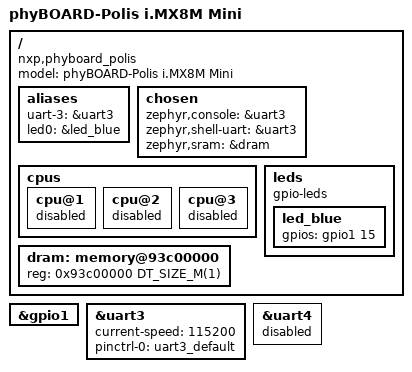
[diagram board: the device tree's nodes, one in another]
/*
 * Copyright (c) 2026 BayLibre SAS
 *
 * SPDX-License-Identifier: Apache-2.0
 */

/dts-v1/;

#include <nxp/nxp_mimx8mm_a53.dtsi>
#include <zephyr/dt-bindings/gpio/gpio.h>
#include "phyboard_polis-pinctrl.dtsi"

/ {
	model = "phyBOARD-Polis i.MX8M Mini";
	compatible = "nxp,phyboard_polis";

	aliases {
		uart-3 = &uart3;
		led0 = &led_blue;
	};

	chosen {
		zephyr,console = &uart3;
		zephyr,shell-uart = &uart3;
		/* sram node actually locates at DDR DRAM */
		zephyr,sram = &dram;
	};

	cpus {
		cpu@1 {
			status = "disabled";
		};

		cpu@2 {
			status = "disabled";
		};

		cpu@3 {
			status = "disabled";
		};
	};

	dram: memory@93c00000 {
		reg = <0x93c00000 DT_SIZE_M(1)>;
	};

	leds {
		compatible = "gpio-leds";

		led_blue: led_blue {
			gpios = <&gpio1 15 GPIO_ACTIVE_HIGH>;
		};
	};
};

&gpio1 {
	status = "okay";
};

/* UART usually used from A53 Core (1st tty on Debug USB connector) */
&uart3 {
	status = "okay";
	current-speed = <115200>;
	pinctrl-0 = <&uart3_default>;
	pinctrl-names = "default";
};

/* UART of the M4 Core (2nd tty on Debug USB connector) */
&uart4 {
	status = "disabled";
};
